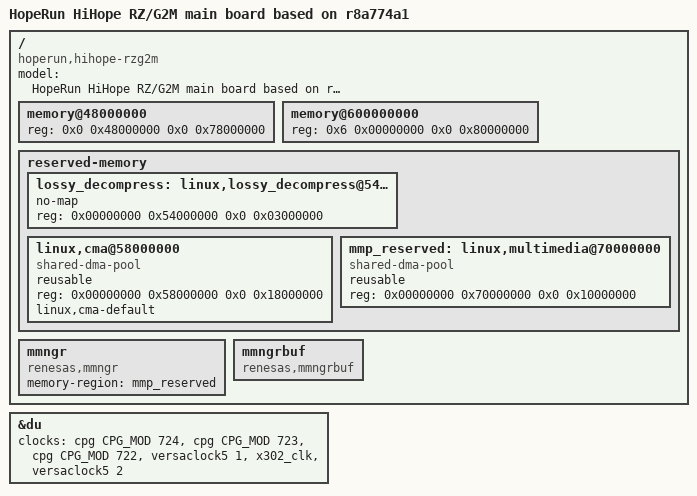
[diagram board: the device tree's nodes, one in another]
// SPDX-License-Identifier: GPL-2.0
/*
 * Device Tree Source for the HiHope RZ/G2M Rev.3.0/4.0 main board
 *
 * Copyright (C) 2020 Renesas Electronics Corp.
 */

/dts-v1/;
#include "r8a774a1.dtsi"
#include "hihope-rev4.dtsi"

/ {
	model = "HopeRun HiHope RZ/G2M main board based on r8a774a1";
	compatible = "hoperun,hihope-rzg2m", "renesas,r8a774a1";

	memory@48000000 {
		device_type = "memory";
		/* first 128MB is reserved for secure area. */
		reg = <0x0 0x48000000 0x0 0x78000000>;
	};

	memory@600000000 {
		device_type = "memory";
		reg = <0x6 0x00000000 0x0 0x80000000>;
	};

	reserved-memory {
		#address-cells = <2>;
		#size-cells = <2>;
		ranges;

		/* device specific region for Lossy Decompression */
		lossy_decompress: linux,lossy_decompress@54000000 {
			no-map;
			reg = <0x00000000 0x54000000 0x0 0x03000000>;
		};

		/* global autoconfigured region for contiguous allocations */
		linux,cma@58000000 {
			compatible = "shared-dma-pool";
			reusable;
			reg = <0x00000000 0x58000000 0x0 0x18000000>;
			linux,cma-default;
		};

		/* device specific region for contiguous allocations */
		mmp_reserved: linux,multimedia@70000000 {
			compatible = "shared-dma-pool";
			reusable;
			reg = <0x00000000 0x70000000 0x0 0x10000000>;
		};
	};

	mmngr {
		compatible = "renesas,mmngr";
		memory-region = <&mmp_reserved>;
	};

	mmngrbuf {
		compatible = "renesas,mmngrbuf";
	};
};

&du {
	clocks = <&cpg CPG_MOD 724>,
		 <&cpg CPG_MOD 723>,
		 <&cpg CPG_MOD 722>,
		 <&versaclock5 1>,
		 <&x302_clk>,
		 <&versaclock5 2>;
	clock-names = "du.0", "du.1", "du.2",
		      "dclkin.0", "dclkin.1", "dclkin.2";
};
